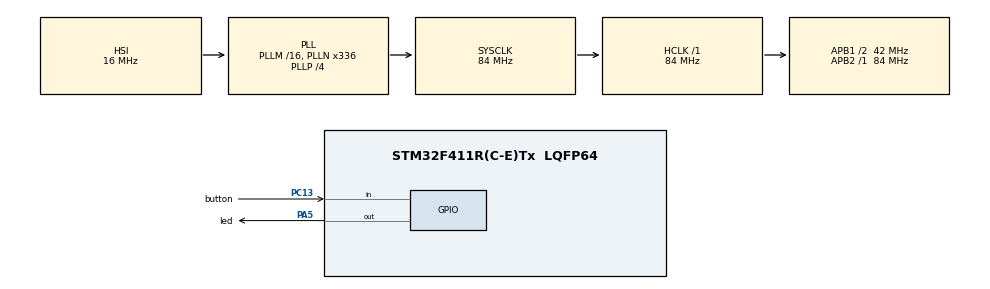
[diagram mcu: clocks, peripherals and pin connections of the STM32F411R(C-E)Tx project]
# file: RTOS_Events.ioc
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FREERTOS.Events01=ledControlEvent,Dynamic,NULL;otherControlEvent,Dynamic,NULL
FREERTOS.Tasks01=ledTask,32,128,ledTaskControl,Default,NULL,Dynamic,NULL,NULL;button,32,128,buttonControl,Default,NULL,Dynamic,NULL,NULL;sensor,32,128,sensorControl,Default,NULL,Dynamic,NULL,NULL
FREERTOS.configUSE_NEWLIB_REENTRANT=1
Mcu.Family=STM32F4
Mcu.Name=STM32F411R(C-E)Tx
Mcu.Package=LQFP64
NVIC.PriorityGroup=NVIC_PRIORITYGROUP_4
NVIC.TIM5_IRQn=true\:15\:0\:false\:false\:true\:false\:false\:true\:true
NVIC.TimeBase=TIM5_IRQn
NVIC.TimeBaseIP=TIM5
PA13.Mode=Serial_Wire
PA13.Signal=SYS_JTMS-SWDIO
PA14.Mode=Serial_Wire
PA14.Signal=SYS_JTCK-SWCLK
PA5.GPIO_Label=led
PA5.GPIO_Speed=GPIO_SPEED_FREQ_HIGH
PA5.Signal=GPIO_Output
PC13-ANTI_TAMP.GPIO_Label=button
PC13-ANTI_TAMP.GPIO_PuPd=GPIO_PULLUP
PC13-ANTI_TAMP.Signal=GPIO_Input
ProjectManager.HeapSize=0x200
ProjectManager.StackSize=0x400
ProjectManager.TargetToolchain=STM32CubeIDE
RCC.48MHZClocksFreq_Value=84000000
RCC.AHBFreq_Value=84000000
RCC.APB1CLKDivider=RCC_HCLK_DIV2
RCC.APB1Freq_Value=42000000
RCC.APB1TimFreq_Value=84000000
RCC.APB2Freq_Value=84000000
RCC.APB2TimFreq_Value=84000000
RCC.CortexFreq_Value=84000000
RCC.FLatency-AdvancedSettings=FLASH_LATENCY_2
RCC.HCLKFreq_Value=84000000
RCC.HSE_VALUE=8000000
RCC.HSI_VALUE=16000000
RCC.PLLN=336
RCC.PLLP=RCC_PLLP_DIV4
RCC.SYSCLKFreq_VALUE=84000000
RCC.SYSCLKSource=RCC_SYSCLKSOURCE_PLLCLK
RCC.VCOOutputFreq_Value=336000000
VP_FREERTOS_VS_CMSIS_V2.Mode=CMSIS_V2
VP_SYS_VS_tim5.Mode=TIM5
board=NUCLEO-F411RE

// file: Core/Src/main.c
/* USER CODE BEGIN Header */
/**
 ******************************************************************************
 * @file           : main.c
 * @brief          : Main program body
 ******************************************************************************
 * @attention
 *
 * Copyright (c) 2025 STMicroelectronics.
 * All rights reserved.
 *
 * This software is licensed under terms that can be found in the LICENSE file
 * in the root directory of this software component.
 * If no LICENSE file comes with this software, it is provided AS-IS.
 *
 ******************************************************************************
 */
/* USER CODE END Header */
#include "main.h"
#include "cmsis_os.h"

/* USER CODE BEGIN Includes */
#include "stdio.h"
/* USER CODE END Includes */

/* Definitions for ledTask */
osThreadId_t ledTaskHandle;
const osThreadAttr_t ledTask_attributes = { .name = "ledTask", .stack_size = 128
		* 4, .priority = (osPriority_t) osPriorityAboveNormal, };
/* Definitions for button */
osThreadId_t buttonHandle;
const osThreadAttr_t button_attributes = { .name = "button", .stack_size = 128
		* 4, .priority = (osPriority_t) osPriorityAboveNormal, };
/* Definitions for sensor */
osThreadId_t sensorHandle;
const osThreadAttr_t sensor_attributes = { .name = "sensor", .stack_size = 128
		* 4, .priority = (osPriority_t) osPriorityAboveNormal, };
/* Definitions for ledControlEvent */
osEventFlagsId_t ledControlEventHandle;
const osEventFlagsAttr_t ledControlEvent_attributes = { .name =
		"ledControlEvent" };
/* Definitions for otherControlEvent */
osEventFlagsId_t otherControlEventHandle;
const osEventFlagsAttr_t otherControlEvent_attributes = { .name =
		"otherControlEvent" };

void SystemClock_Config(void);
static void MX_GPIO_Init(void);
void ledTaskControl(void *argument);
void buttonControl(void *argument);
void sensorControl(void *argument);

/* USER CODE BEGIN 0 */
int _write(int file, char *ptr, int len) {
	/* Implement your write code here, this is used by puts and printf for example */
	int i = 0;
	for (i = 0; i < len; i++)
		ITM_SendChar((*ptr++));
	return len;
}
/* USER CODE END 0 */

int main(void) {

	/* MCU Configuration--------------------------------------------------------*/

	/* Reset of all peripherals, Initializes the Flash interface and the Systick. */
	HAL_Init();

	/* Configure the system clock */
	SystemClock_Config();

	/* Initialize all configured peripherals */
	MX_GPIO_Init();

	/* Init scheduler */
	osKernelInitialize();

	/* Create the thread(s) */
	/* creation of ledTask */
	ledTaskHandle = osThreadNew(ledTaskControl, NULL, &ledTask_attributes);

	/* creation of button */
	buttonHandle = osThreadNew(buttonControl, NULL, &button_attributes);

	/* creation of sensor */
	sensorHandle = osThreadNew(sensorControl, NULL, &sensor_attributes);

	/* Create the event(s) */
	/* creation of ledControlEvent */
	ledControlEventHandle = osEventFlagsNew(&ledControlEvent_attributes);

	/* creation of otherControlEvent */
	otherControlEventHandle = osEventFlagsNew(&otherControlEvent_attributes);

	/* Start scheduler */
	osKernelStart();

	/* We should never get here as control is now taken by the scheduler */

	/* Infinite loop */
	while (1) {

	}
}

void SystemClock_Config(void) {
	RCC_OscInitTypeDef RCC_OscInitStruct = { 0 };
	RCC_ClkInitTypeDef RCC_ClkInitStruct = { 0 };

	/** Configure the main internal regulator output voltage
	 */
	__HAL_RCC_PWR_CLK_ENABLE();
	__HAL_PWR_VOLTAGESCALING_CONFIG(PWR_REGULATOR_VOLTAGE_SCALE1);

	/** Initializes the RCC Oscillators according to the specified parameters
	 * in the RCC_OscInitTypeDef structure.
	 */
	RCC_OscInitStruct.OscillatorType = RCC_OSCILLATORTYPE_HSI;
	RCC_OscInitStruct.HSIState = RCC_HSI_ON;
	RCC_OscInitStruct.HSICalibrationValue = RCC_HSICALIBRATION_DEFAULT;
	RCC_OscInitStruct.PLL.PLLState = RCC_PLL_ON;
	RCC_OscInitStruct.PLL.PLLSource = RCC_PLLSOURCE_HSI;
	RCC_OscInitStruct.PLL.PLLM = 16;
	RCC_OscInitStruct.PLL.PLLN = 336;
	RCC_OscInitStruct.PLL.PLLP = RCC_PLLP_DIV4;
	RCC_OscInitStruct.PLL.PLLQ = 4;
	if (HAL_RCC_OscConfig(&RCC_OscInitStruct) != HAL_OK) {
		Error_Handler();
	}

	/** Initializes the CPU, AHB and APB buses clocks
	 */
	RCC_ClkInitStruct.ClockType = RCC_CLOCKTYPE_HCLK | RCC_CLOCKTYPE_SYSCLK
			| RCC_CLOCKTYPE_PCLK1 | RCC_CLOCKTYPE_PCLK2;
	RCC_ClkInitStruct.SYSCLKSource = RCC_SYSCLKSOURCE_PLLCLK;
	RCC_ClkInitStruct.AHBCLKDivider = RCC_SYSCLK_DIV1;
	RCC_ClkInitStruct.APB1CLKDivider = RCC_HCLK_DIV2;
	RCC_ClkInitStruct.APB2CLKDivider = RCC_HCLK_DIV1;

	if (HAL_RCC_ClockConfig(&RCC_ClkInitStruct, FLASH_LATENCY_2) != HAL_OK) {
		Error_Handler();
	}
}

static void MX_GPIO_Init(void) {
	GPIO_InitTypeDef GPIO_InitStruct = { 0 };

	/* GPIO Ports Clock Enable */
	__HAL_RCC_GPIOC_CLK_ENABLE();
	__HAL_RCC_GPIOA_CLK_ENABLE();

	/*Configure GPIO pin Output Level */
	HAL_GPIO_WritePin(led_GPIO_Port, led_Pin, GPIO_PIN_RESET);

	/*Configure GPIO pin : button_Pin */
	GPIO_InitStruct.Pin = button_Pin;
	GPIO_InitStruct.Mode = GPIO_MODE_INPUT;
	GPIO_InitStruct.Pull = GPIO_PULLUP;
	HAL_GPIO_Init(button_GPIO_Port, &GPIO_InitStruct);

	/*Configure GPIO pin : led_Pin */
	GPIO_InitStruct.Pin = led_Pin;
	GPIO_InitStruct.Mode = GPIO_MODE_OUTPUT_PP;
	GPIO_InitStruct.Pull = GPIO_NOPULL;
	GPIO_InitStruct.Speed = GPIO_SPEED_FREQ_HIGH;
	HAL_GPIO_Init(led_GPIO_Port, &GPIO_InitStruct);

}

void ledTaskControl(void *argument) {
	/* USER CODE BEGIN 5 */
	/* Infinite loop */
	for (;;) {
		uint32_t flags = osEventFlagsWait(ledControlEventHandle, 3,
		osFlagsWaitAny, osWaitForever);
		printf("Led Task Flag Value:%lu \r\n", flags);
		if (flags == 3) {
			HAL_GPIO_TogglePin(led_GPIO_Port, led_Pin);
		}
		osDelay(200);
	}
	/* USER CODE END 5 */
}

void buttonControl(void *argument) {
	/* USER CODE BEGIN buttonControl */
	/* Infinite loop */
	uint32_t flags = 3;
	for (;;) {
		if (!HAL_GPIO_ReadPin(button_GPIO_Port, button_Pin)) {
			osEventFlagsSet(ledControlEventHandle, flags);
			printf("Button Task Flag Value:%lu \r\n", flags);
		}
		osDelay(200);
	}
	/* USER CODE END buttonControl */
}

void sensorControl(void *argument) {
	for (;;) {
		osDelay(1);
	}
}

void HAL_TIM_PeriodElapsedCallback(TIM_HandleTypeDef *htim) {
	if (htim->Instance == TIM5) {
		HAL_IncTick();
	}
}

void Error_Handler(void) {
	__disable_irq();
	while (1) {
	}
}
